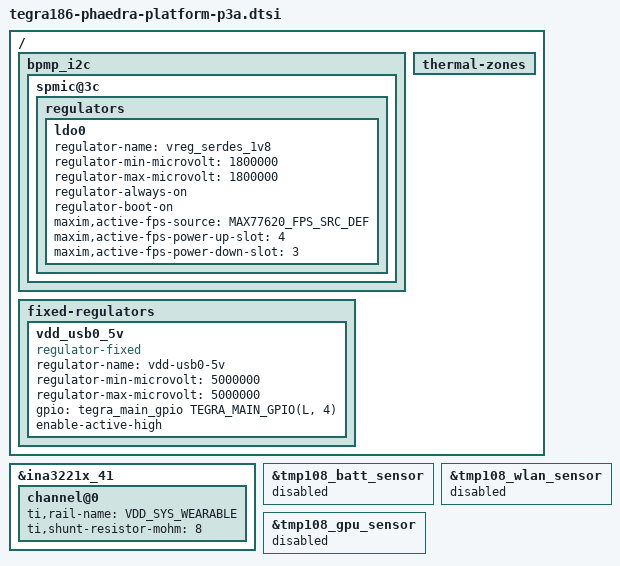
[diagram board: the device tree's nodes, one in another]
/*
 * tegra186-phaedra-platform-p2b.dtsi
 *
 * Main device tree for the phaedra product.
 *
 * Copyright (c) 2017, Magic Leap, Inc.  All rights reserved.
 *
 * This program is free software; you can redistribute it and/or modify
 * it under the terms of the GNU General Public License as published by
 * the Free Software Foundation; version 2 of the License.
 *
 * This program is distributed in the hope that it will be useful, but WITHOUT
 * ANY WARRANTY; without even the implied warranty of MERCHANTABILITY or
 * FITNESS FOR A PARTICULAR PURPOSE.  See the GNU General Public License for
 * more details.
 */

#include "tegra186-platforms/tegra186-phaedra-power.dtsi"

/ {
	bpmp_i2c {
		spmic@3c {
			/* FPS CID4 = 0x58 */
			regulators {
				ldo0 {
					regulator-name = "vreg_serdes_1v8";
					regulator-min-microvolt = <1800000>;
					regulator-max-microvolt = <1800000>;
					regulator-always-on;
					regulator-boot-on;
					maxim,active-fps-source = <MAX77620_FPS_SRC_DEF>;
					maxim,active-fps-power-up-slot = <4>;
					maxim,active-fps-power-down-slot = <3>;
				};
			};
		};
	};

	fixed-regulators {
		/* VREG_OTG_5V0 - TPS61253 */
		vdd_usb0_5v: vdd_usb0_5v {
			compatible = "regulator-fixed";
			regulator-name = "vdd-usb0-5v";
			regulator-min-microvolt = <5000000>;
			regulator-max-microvolt = <5000000>;
			/* DNI - controlled by PD controller */
			gpio = <&tegra_main_gpio TEGRA_MAIN_GPIO(L, 4) 0>;
			enable-active-high;
		};
	};

	thermal-zones {
		/delete-node/ tmp108_batt;
		/delete-node/ tmp108_wlan;
		/delete-node/ tmp108_gpu;
	};
};

&ina3221x_41 {
	channel@0 {
		ti,rail-name = "VDD_SYS_WEARABLE";
		ti,shunt-resistor-mohm = <8>;
	};
};

&tmp108_batt_sensor {
	status = "disabled";
};

&tmp108_wlan_sensor {
	status = "disabled";
};

&tmp108_gpu_sensor {
	status = "disabled";
};
